AUTOSAR XML (schema 4-2-2)
package /ComponentTypes
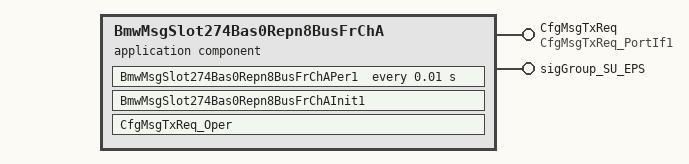
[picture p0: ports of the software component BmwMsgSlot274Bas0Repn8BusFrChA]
  application sw component type BmwMsgSlot274Bas0Repn8BusFrChA
    provide port CfgMsgTxReq: server-com-spec{operation=Oper, queue-length=1}, provided-interface=CfgMsgTxReq_PortIf1
    provide port sigGroup_SU_EPS: nonqueued-sender-com-spec{data-element=sigGroup_SU_EPS, uses-end-to-end-protection=true, init-value=fields=[CRC_SU_EPS:0, UN_TOT_STR_EPS:0, ALIV_SU_EPS:15, TOT_STR_EPS:1228, SU_EPS_dummy_20_51:0, SU_EPS_dummy_14_19:0]}, provided-interface=sigGroup_SU_EPS
    behavior BmwMsgSlot274Bas0Repn8BusFrChA_InternalBehavior: port-api-option{enable-take-address=false, error-handling=NO-TRANSFORMER-ERROR-HANDLING, indirect-api=false, port=sigGroup_SU_EPS}
      ar-typed-per-instance-memorys:
        4 x data, all with sw-calibration-access=READ-ONLY:
          SigGroupSuEps: type=sigGroup_SU_EPS1
          SuEpsBurstCntr: type=uint8
          SuEpsDebCntr: type=uint8
          SuEpsPerCntr: type=uint16
      init event BmwMsgSlot274Bas0Repn8BusFrChA_InitEvent: start-on-event=BmwMsgSlot274Bas0Repn8BusFrChAInit1
      timing event TMT_BmwMsgSlot274Bas0Repn8BusFrChAPer1: start-on-event=BmwMsgSlot274Bas0Repn8BusFrChAPer1, period=0.01
      operation invoked event OIT_CfgMsgTxReq_Oper_CfgMsgTxReq_Oper: start-on-event=CfgMsgTxReq_Oper, operation=CfgMsgTxReq.Oper
      runnable BmwMsgSlot274Bas0Repn8BusFrChAInit1
      runnable BmwMsgSlot274Bas0Repn8BusFrChAPer1
        data-send-points:
          access SEND_sigGroup_SU_EPS_sigGroup_SU_EPS: accessed-variable=sigGroup_SU_EPS.sigGroup_SU_EPS
      runnable CfgMsgTxReq_Oper
  swc implementation BmwMsgSlot274Bas0Repn8BusFrChA_Implementation: behavior=BmwMsgSlot274Bas0Repn8BusFrChA_InternalBehavior
    code-descriptors:
      code Default: artifact-descriptors=autosar-engineering-object={short-label=Default, category=SWSRC}
